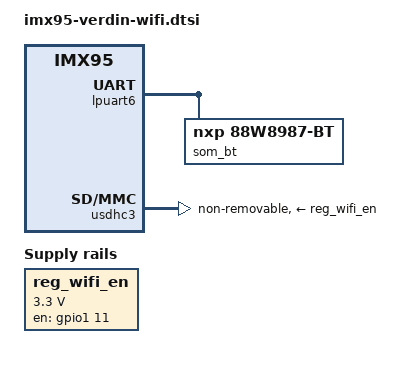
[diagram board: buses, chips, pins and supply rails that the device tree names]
// SPDX-License-Identifier: GPL-2.0-or-later OR MIT
/*
 * Copyright (c) Toradex
 *
 * Common dtsi for Verdin iMX95 SoM WB variant
 *
 * https://www.toradex.com/computer-on-modules/verdin-arm-family/nxp-imx95
 */

/ {
	reg_wifi_en: regulator-wifi-en {
		compatible = "regulator-fixed";
		pinctrl-names = "default";
		pinctrl-0 = <&pinctrl_wifi_pwr_en>;
		/* PMIC_EN_WIFI */
		gpios = <&gpio1 11 GPIO_ACTIVE_HIGH>;
		enable-active-high;
		regulator-max-microvolt = <3300000>;
		regulator-min-microvolt = <3300000>;
		regulator-name = "PDn_MAYA-W260";
		startup-delay-us = <2000>;
	};
};

/* On-module Bluetooth */
&lpuart6 {
	pinctrl-names = "default";
	pinctrl-0 = <&pinctrl_bt_uart>;
	uart-has-rtscts;

	status = "okay";

	som_bt: bluetooth {
		compatible = "nxp,88w8987-bt";
		fw-init-baudrate = <3000000>;
	};
};

/* On-module Wi-Fi */
&usdhc3 {
	pinctrl-names = "default", "state_100mhz", "state_200mhz";
	pinctrl-0 = <&pinctrl_usdhc3>;
	pinctrl-1 = <&pinctrl_usdhc3>;
	pinctrl-2 = <&pinctrl_usdhc3_200mhz>;
	keep-power-in-suspend;
	non-removable;
	vmmc-supply = <&reg_wifi_en>;

	status = "okay";
};
